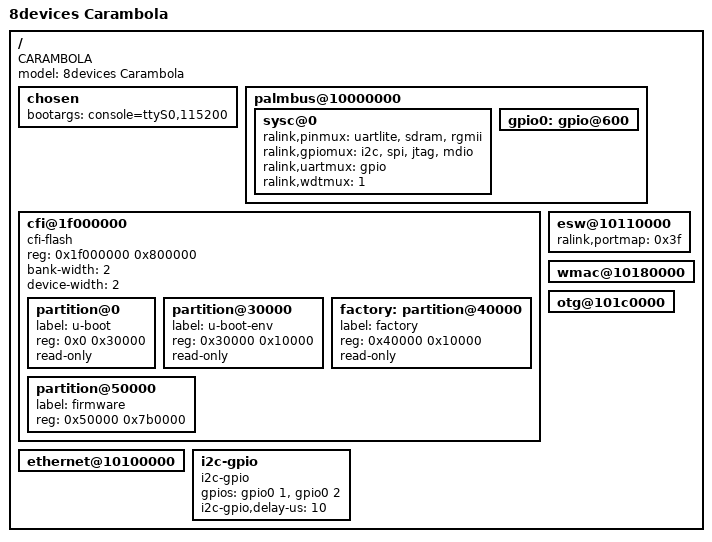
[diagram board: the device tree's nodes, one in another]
/dts-v1/;

/include/ "rt3050.dtsi"

/ {
	compatible = "CARAMBOLA", "ralink,rt3050-soc";
	model = "8devices Carambola";

	chosen {
		bootargs = "console=ttyS0,115200";
	};

	palmbus@10000000 {
		sysc@0 {
			ralink,pinmux = "uartlite", "sdram", "rgmii";
			ralink,gpiomux = "i2c", "spi", "jtag", "mdio";
			ralink,uartmux = "gpio";
			ralink,wdtmux = <1>;
		};

		gpio0: gpio@600 {
			status = "okay";
		};

	};

	cfi@1f000000 {
		compatible = "cfi-flash";
		reg = <0x1f000000 0x800000>;

		bank-width = <2>;
		device-width = <2>;
		#address-cells = <1>;
		#size-cells = <1>;

		partition@0 {
			label = "u-boot";
			reg = <0x0 0x30000>;
			read-only;
		};

		partition@30000 {
			label = "u-boot-env";
			reg = <0x30000 0x10000>;
			read-only;
		};

		factory: partition@40000 {
			label = "factory";
			reg = <0x40000 0x10000>;
			read-only;
		};

		partition@50000 {
			label = "firmware";
			reg = <0x50000 0x7b0000>;
		};
	};

	ethernet@10100000 {
		status = "okay";
	};

	esw@10110000 {
		status = "okay";
		ralink,portmap = <0x3f>;
	};

	wmac@10180000 {
		status = "okay";
	};

	otg@101c0000 {
		status = "okay";
	};

	i2c-gpio {
		compatible = "i2c-gpio";

		gpios = <&gpio0 1 0 &gpio0 2 0>;
		i2c-gpio,delay-us = <10>;
	};
};
